# STM32H7A3xx register map
File version: 1.0
Registers are 32-bit, access not given, reset 0x0 unless marked. A register's access mark holds for its fields unless they carry their own. Offsets are from the block's base; [hi:lo] are bit positions; {n}, {i} and the like mark numbered series; 'fields as' and 'values as' point back to an identical list.

## WWDG1
Base 0x50003000
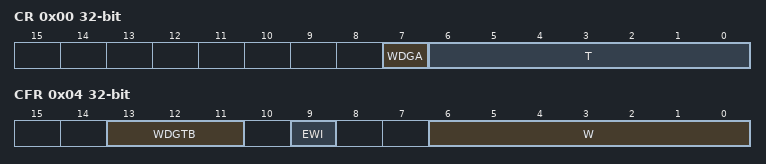
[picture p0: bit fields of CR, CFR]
0x00 CR
  [7] WDGA, [6:0] T
0x04 CFR
  [13:11] WDGTB, [9] EWI, [6:0] W
0x08 SR
  [0] EWIF

## GPV
Base 0x51000000
{0x1FC0+4i} AXI_PERIPH_ID_{i} (i=4..7)
{0x1FE0+4i} AXI_PERIPH_ID_{i} (i=0..3)
{0x1FF0+4i} AXI_COMP_ID_{i} (i=0..3)
{0x1008+0x1000*i} AXI_TARG{i}_FN_MOD_ISS_BM (i=1..10)
0x2024 AXI_TARG1_FN_MOD2
0x202C AXI_TARG1_FN_MOD_LB
0x2108 AXI_TARG1_FN_MOD
0x3024 AXI_TARG2_FN_MOD2
0x302C AXI_TARG2_FN_MOD_LB
0x3108 AXI_TARG2_FN_MOD
{0x1024+0x1000*i} AXI_TARG{i}_FN_MOD2 (i=7..10)
0x802C AXI_TARG7_FN_MOD_LB
{0x1108+0x1000*i} AXI_TARG{i}_FN_MOD (i=7..10)
0xC02C AXI_TARG10_FN_MOD_LB
0x42024 AXI_INI1_FN_MOD2
0x42028 AXI_INI1_FN_MOD_AHB
{0x41100+0x1000*i} AXI_INI{i}_READ_QOS (i=1..7)
{0x41104+0x1000*i} AXI_INI{i}_WRITE_QOS (i=1..7)
{0x41108+0x1000*i} AXI_INI{i}_FN_MOD (i=1..7)
0x44024 AXI_INI3_FN_MOD2
0x44028 AXI_INI3_FN_MOD_AHB
0x48024 AXI_INI7_FN_MOD2
0x48028 AXI_INI7_FN_MOD_AHB

## FLASH
Base 0x52002000
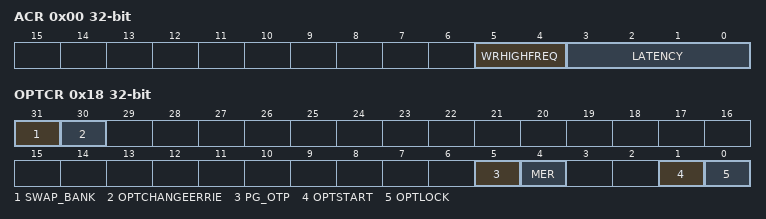
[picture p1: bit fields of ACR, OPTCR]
0x00 ACR
  [5:4] WRHIGHFREQ, [3:0] LATENCY
0x04 KEYR1
0x08 OPTKEYR
0x0C CR1
0x10 SR1
0x14 CCR1
0x18 OPTCR
  [31] SWAP_BANK, [30] OPTCHANGEERRIE, [5] PG_OTP, [4] MER, [1] OPTSTART, [0] OPTLOCK
0x1C OPTSR_CUR
0x20 OPTSR_PRG
0x24 OPTCCR
  [30] CLR_OPTCHANGEERR
0x28 PRAR_CUR1
0x2C PRAR_PRG1
0x30 SCAR_CUR1
0x34 SCAR_PRG1
0x38 WPSN_CUR1
0x3C WPSN_PRG1
0x40 BOOT_CUR
0x44 BOOT_PRG
0x50 CRCCR1
0x54 CRCSADD1
0x58 CRCEADD1
0x5C CRCDATA
  [31:0] CRC_DATA
0x60 ECC_FA1
0x68 OTPBL_CUR
0x6C OTPBL_PRG
0x104 KEYR2
0x10C CR2
0x110 SR2
0x114 CCR2
0x128 PRAR_CUR2
0x12C PRAR_PRG2
0x130 SCAR_CUR2
0x134 SCAR_PRG2
0x138 WPSN_CUR2
0x13C WPSN_PRG2
0x150 CRCCR2
0x154 CRCSADD2
0x158 CRCEADD2
0x15C CRCDATA2
0x160 ECC_FA2

## FMC_Bank1_R
Base 0x52004000
0x00 BTCR.0
0x04 BTCR.1
0x08 BTCR.2
0x0C BTCR.3
0x10 BTCR.4
0x14 BTCR.5
0x18 BTCR.6
0x1C BTCR.7

## FMC_Bank2_R
Base 0x52004060
0x00 PCR2
0x04 SR2
0x08 PMEM2
0x0C PATT2
0x14 ECCR2

## FMC_Bank3_R
Base 0x52004080
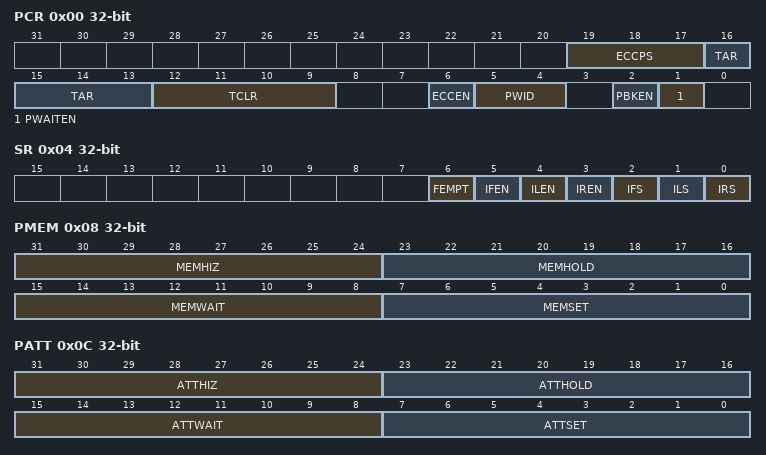
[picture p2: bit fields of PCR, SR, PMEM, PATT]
0x00 PCR
  [19:17] ECCPS, [16:13] TAR, [12:9] TCLR, [6] ECCEN, [5:4] PWID, [2] PBKEN, [1] PWAITEN
0x04 SR
  [6] FEMPT, [5] IFEN, [4] ILEN, [3] IREN, [2] IFS, [1] ILS, [0] IRS
0x08 PMEM
  [31:24] MEMHIZ, [23:16] MEMHOLD, [15:8] MEMWAIT, [7:0] MEMSET
0x0C PATT
  [31:24] ATTHIZ, [23:16] ATTHOLD, [15:8] ATTWAIT, [7:0] ATTSET
0x14 ECCR

## FMC_Bank1E_R
Base 0x52004104
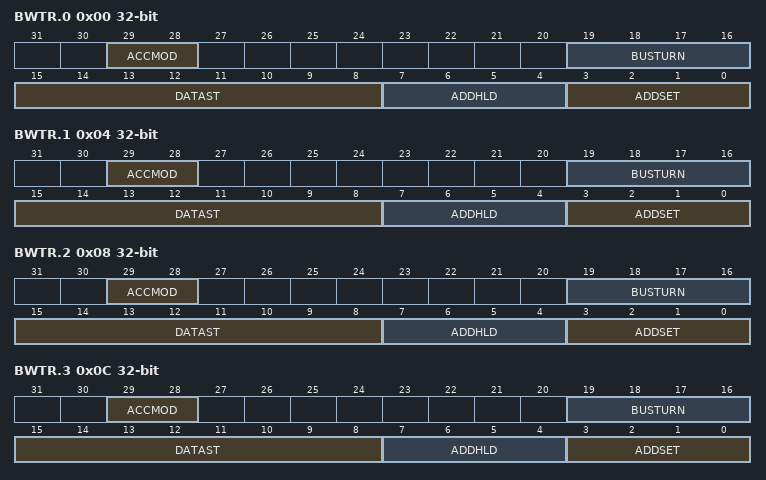
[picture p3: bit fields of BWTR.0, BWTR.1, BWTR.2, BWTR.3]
0x00 BWTR.0
  [29:28] ACCMOD, [19:16] BUSTURN, [15:8] DATAST, [7:4] ADDHLD, [3:0] ADDSET
0x04 BWTR.1
  fields as BWTR.0
0x08 BWTR.2
  fields as BWTR.0
0x0C BWTR.3
  fields as BWTR.0
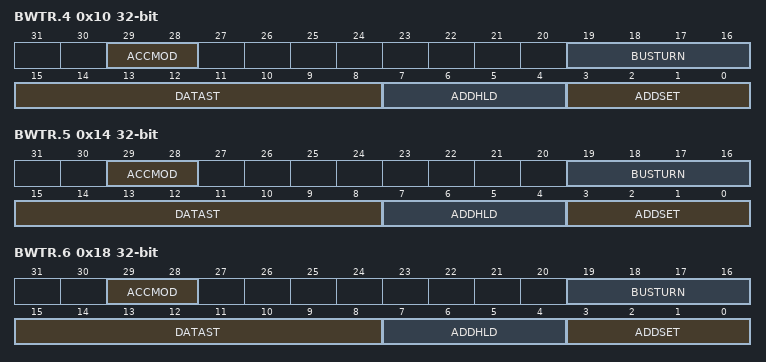
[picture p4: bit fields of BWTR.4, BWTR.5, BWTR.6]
0x10 BWTR.4
  fields as BWTR.0
0x14 BWTR.5
  fields as BWTR.0
0x18 BWTR.6
  fields as BWTR.0

## FMC_Bank5_6_R
Base 0x52004140
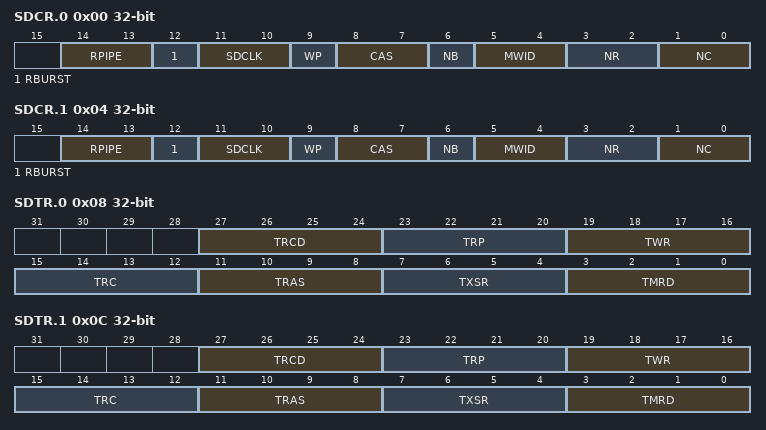
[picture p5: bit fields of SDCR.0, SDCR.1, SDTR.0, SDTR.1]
0x00 SDCR.0
  [14:13] RPIPE, [12] RBURST, [11:10] SDCLK, [9] WP, [8:7] CAS, [6] NB, [5:4] MWID, [3:2] NR, [1:0] NC
0x04 SDCR.1
  fields as SDCR.0
0x08 SDTR.0
  [27:24] TRCD, [23:20] TRP, [19:16] TWR, [15:12] TRC, [11:8] TRAS, [7:4] TXSR, [3:0] TMRD
0x0C SDTR.1
  fields as SDTR.0
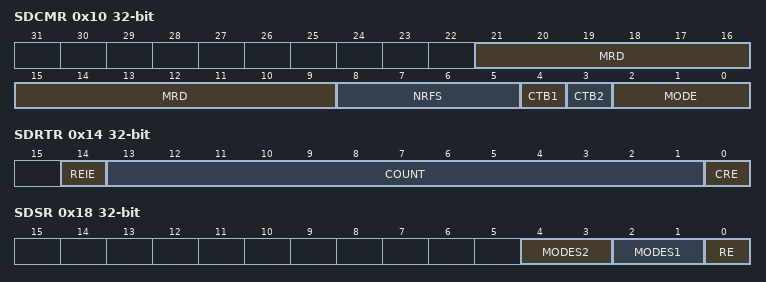
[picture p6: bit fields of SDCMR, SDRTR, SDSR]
0x10 SDCMR
  [21:9] MRD, [8:5] NRFS, [4] CTB1, [3] CTB2, [2:0] MODE
0x14 SDRTR
  [14] REIE, [13:1] COUNT, [0] CRE
0x18 SDSR
  [4:3] MODES2, [2:1] MODES1, [0] RE

## OCTOSPI1
Base 0x52005000
Same registers: OCTOSPI2 0x5200A000
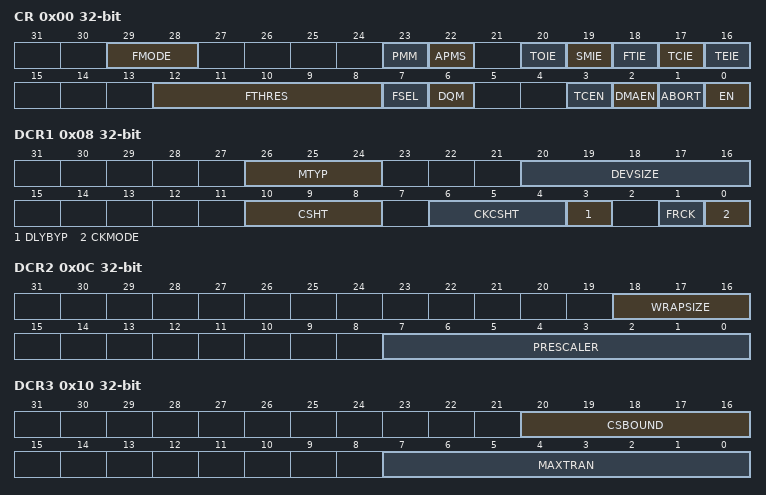
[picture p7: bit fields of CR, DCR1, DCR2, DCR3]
0x00 CR
  [29:28] FMODE, [23] PMM, [22] APMS, [20] TOIE, [19] SMIE, [18] FTIE, [17] TCIE, [16] TEIE, [12:8] FTHRES, [7] FSEL, [6] DQM, [3] TCEN, [2] DMAEN, [1] ABORT, [0] EN
0x08 DCR1
  [26:24] MTYP, [20:16] DEVSIZE, [10:8] CSHT, [6:4] CKCSHT, [3] DLYBYP, [1] FRCK, [0] CKMODE
0x0C DCR2
  [18:16] WRAPSIZE, [7:0] PRESCALER
0x10 DCR3
  [20:16] CSBOUND, [7:0] MAXTRAN
0x14 DCR4
  [31:0] REFRESH
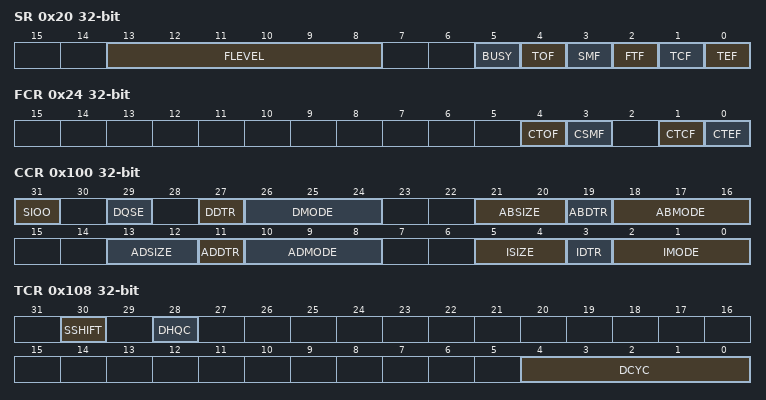
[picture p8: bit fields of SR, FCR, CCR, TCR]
0x20 SR
  [13:8] FLEVEL, [5] BUSY, [4] TOF, [3] SMF, [2] FTF, [1] TCF, [0] TEF
0x24 FCR
  [4] CTOF, [3] CSMF, [1] CTCF, [0] CTEF
0x40 DLR
  [31:0] DL
0x48 AR
  [31:0] ADDRESS
0x50 DR
  [31:0] DATA
0x80 PSMKR
  [31:0] MASK
0x88 PSMAR
  [31:0] MATCH
0x90 PIR
  [15:0] INTERVAL
0x100 CCR
  [31] SIOO, [29] DQSE, [27] DDTR, [26:24] DMODE, [21:20] ABSIZE, [19] ABDTR, [18:16] ABMODE, [13:12] ADSIZE, [11] ADDTR, [10:8] ADMODE, [5:4] ISIZE, [3] IDTR, [2:0] IMODE
0x108 TCR
  [30] SSHIFT, [28] DHQC, [4:0] DCYC
0x110 IR
  [31:0] INSTRUCTION
0x120 ABR
  [31:0] ALTERNATE
0x130 LPTR
  [15:0] TIMEOUT
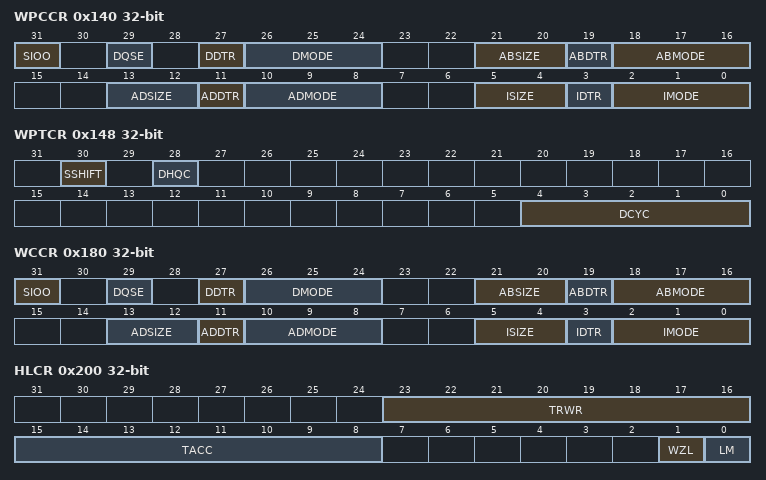
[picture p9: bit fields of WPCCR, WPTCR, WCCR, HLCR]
0x140 WPCCR
  fields as CCR
0x148 WPTCR
  [30] SSHIFT, [28] DHQC, [4:0] DCYC
0x150 WPIR
  [31:0] INSTRUCTION
0x160 WPABR
  [31:0] ALTERNATE
0x180 WCCR
  fields as CCR
0x188 WTCR
  [4:0] DCYC
0x190 WIR
  [31:0] INSTRUCTION
0x1A0 WABR
  [31:0] ALTERNATE
0x200 HLCR
  [23:16] TRWR, [15:8] TACC, [1] WZL, [0] LM
0x3EC HWCFGR
0x3F0 VER
  [7:0] VER
0x3F4 ID
0x3F8 MID
